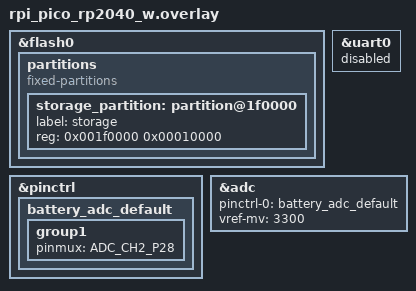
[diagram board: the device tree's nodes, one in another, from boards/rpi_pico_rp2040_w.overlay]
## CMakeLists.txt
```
cmake_minimum_required(VERSION 3.20.0)
find_package(Zephyr REQUIRED HINTS $ENV{ZEPHYR_BASE})
project(ham_lab_powermeter)
target_sources(app PRIVATE src/main.c src/curves/curves_core.c src/curves/curves_store.c src/network/network.c src/network/tcp_console.c src/network/ntp_clock.c)
```

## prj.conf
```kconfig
CONFIG_GPIO=y
CONFIG_NETWORKING=y
CONFIG_NET_IPV4=y
CONFIG_NET_DHCPV4=y
CONFIG_NET_TCP=y
CONFIG_NET_SOCKETS=y
CONFIG_WIFI=y
CONFIG_NET_MGMT=y
CONFIG_NET_MGMT_EVENT=y
CONFIG_NET_SHELL=y
CONFIG_SHELL=y
CONFIG_SHELL_BACKEND_SERIAL=y
CONFIG_SHELL_BACKEND_TELNET=n
CONFIG_SHELL_BACKEND_DUMMY=y
CONFIG_SHELL_BACKEND_DUMMY_BUF_SIZE=8192
CONFIG_MAIN_STACK_SIZE=4096
CONFIG_SYSTEM_WORKQUEUE_STACK_SIZE=2048
CONFIG_HEAP_MEM_POOL_SIZE=8192
CONFIG_LOG=y
CONFIG_PICOLIBC_IO_FLOAT=y
CONFIG_UDC_DRIVER_LOG_LEVEL_OFF=y
CONFIG_SHELL_STACK_SIZE=5200
CONFIG_NET_TX_STACK_SIZE=2048
CONFIG_NET_RX_STACK_SIZE=2048
CONFIG_NET_PKT_RX_COUNT=16
CONFIG_NET_PKT_TX_COUNT=32
CONFIG_NET_BUF_RX_COUNT=32
CONFIG_NET_BUF_TX_COUNT=64
CONFIG_NET_MAX_CONTEXTS=16
CONFIG_NET_MAX_CONN=16
CONFIG_WIFI_USAGE_MODE_STA_AP=y
CONFIG_NET_L2_WIFI_MGMT=y
CONFIG_NET_L2_WIFI_SHELL=y
CONFIG_NET_CONNECTION_MANAGER=y
CONFIG_NET_MGMT_EVENT_STACK_SIZE=1536
CONFIG_NET_MGMT_EVENT_QUEUE_TIMEOUT=5000
CONFIG_NET_MGMT_EVENT_QUEUE_SIZE=16
CONFIG_WIFI_CREDENTIALS=y
CONFIG_WIFI_CREDENTIALS_BACKEND_SETTINGS=y
CONFIG_SETTINGS=y
CONFIG_FLASH=y
CONFIG_FLASH_MAP=y
CONFIG_NVS=y
CONFIG_SETTINGS_NVS=y
CONFIG_USBD_CDC_ACM_BUF_POOL=y
CONFIG_USBD_CDC_ACM_BUF_POOL_SIZE=4096

# RP2040 bring-up: timer-based RNG for Zephyr networking (not cryptographic).
CONFIG_TEST_RANDOM_GENERATOR=y
CONFIG_TIMER_RANDOM_GENERATOR=y

# UTC measurement timestamps from NTP over WLAN.
CONFIG_NET_UDP=y
CONFIG_DNS_RESOLVER=y
CONFIG_NET_DHCPV4_OPTION_DNS_ADDRESS=y
CONFIG_SNTP=y

CONFIG_ADC=y

# AP test: native DHCP server, two clients; mode remains RAM-only.
CONFIG_NET_DHCPV4_SERVER=y
CONFIG_NET_DHCPV4_SERVER_ADDR_COUNT=2
CONFIG_NET_MGMT_EVENT_INFO=y
```

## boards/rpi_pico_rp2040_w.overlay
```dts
#include <zephyr/dt-bindings/pinctrl/rpi-pico-rp2040-pinctrl.h>
/* Powermeter GPIO pins are configured directly by the application. */

/* Pico W: reserve final 64 KiB of 2 MiB flash for Settings/NVS. */
&flash0 {
    partitions {
        compatible = "fixed-partitions";
        #address-cells = <1>;
        #size-cells = <1>;

        storage_partition: partition@1f0000 {
            label = "storage";
            reg = <0x001f0000 0x00010000>;
        };
    };
};

/* GP0/GP1 belong to software I2C; console is USB CDC ACM. */
&uart0 { status = "disabled"; };

&pinctrl {
    battery_adc_default: battery_adc_default {
        group1 { pinmux = <ADC_CH2_P28>; };
    };
};
&adc {
    status = "okay";
    pinctrl-0 = <&battery_adc_default>;
    pinctrl-names = "default";
    vref-mv = <3300>;
};
```

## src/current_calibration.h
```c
#ifndef CURRENT_CALIBRATION_H
#define CURRENT_CALIBRATION_H
#include <math.h>
#include <stdbool.h>
#include <stddef.h>
#include "curves/curves_store.h"
/* Paired A0 master / A2 measurements, 2026-10-06, 7.1 MHz.
 * A0 watts are the reference, not ICOM percentage or former scope curve.
 * 1 percent excluded: A0 below calibrated floor. 90/100 percent pooled:
 * indistinguishable A2 voltage within sample scatter. Endpoint guards cover
 * only observed endpoint sample voltages, with constant endpoint watts.
 * Resistive 50 ohms ONLY. No extrapolation outside measured voltage bounds. */
#define CURRENT_CALIBRATION_HZ 7100000U
#define CURRENT_MIN_W (hamlab_curve(CURVE_CURRENT)->points[0].w)
#define CURRENT_MAX_W (current_max_w())
#define CURRENT_PLATEAU_V (current_plateau_v())
static const __attribute__((unused)) struct {double v,w;} current_curve[]={
    {0.019687500000,1.494300000000},
    {0.019713566667,1.494300000000},
    {0.039494800000,2.104700000000},
    {0.056960933333,2.586900000000},
    {0.086549466667,3.726366666667},
    {0.243015633333,10.410466666667},
    {0.281750000000,12.822733333333},
    {0.321697900000,16.678633333333},
    {0.385187500000,25.142500000000},
    {0.436041666667,35.765400000000},
    {0.479604166667,47.222500000000},
    {0.502822933333,55.466933333333},
    {0.525354166667,65.059266666667},
    {0.543625000000,74.074366666667},
    {0.558520816667,83.346166666667},
    {0.560062500000,83.346166666667},
};
static inline double current_max_w(void){const struct curve_data *c=hamlab_curve(CURVE_CURRENT);return c->points[c->count-1].w;}
static inline double current_plateau_v(void){
    const struct curve_data *c=hamlab_curve(CURVE_CURRENT);size_t i=c->count-1;
    while(i>0&&c->points[i-1].w==c->points[c->count-1].w)i--;
    return c->points[i].v;
}
static inline bool current_power(double v,double *w){
    return curves_interpolate(hamlab_curve(CURVE_CURRENT),v,w);
}
#endif
```

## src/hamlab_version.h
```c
#ifndef HAMLAB_VERSION_H_
#define HAMLAB_VERSION_H_

#define HAMLAB_VERSION "0.1.49"

#endif
```

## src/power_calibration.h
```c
#ifndef POWER_CALIBRATION_H
#define POWER_CALIBRATION_H
#include <stdbool.h>
#include <stddef.h>
#include <math.h>
#include "curves/curves_store.h"
/* ADC-side voltages, divider included. Scope sine Vpp^2/(8*50).
 * Provisional, ONLY measured at 7031670 Hz. No extrapolation or zero anchor. */
static const __attribute__((unused)) struct { double v, w; } forward_curve[] = {
    {0.0556641,1.2544},
    {0.0860469,1.6384},
    {0.1380937,2.2500},
    {0.1790000,2.7556},
    {0.2404375,4.0000},
    {0.5645938,10.7584},
    {0.6690312,13.2496},
    {0.7982813,17.3056},
    {1.0539375,26.0100},
    {1.3049375,37.2100},
    {1.5681875,49.0000},
    {1.7332500,57.7600},
    {1.8861250,67.2400},
    {2.0262500,75.6900},
    {2.1535000,84.6400},
    {2.2778750,92.1600},
};
static inline bool forward_power(double v, double *w) {
    return curves_interpolate(hamlab_curve(CURVE_FORWARD),v,w);
}
/* Reversed coupler, 50-ohm reference, averaged/pooled repetitions.
 * Runtime selection is RAM-only. No automatic RF frequency detection. */
static unsigned int reverse_calibration_hz=7100000;
struct reverse_cal_point { double v,w; };
static const __attribute__((unused)) struct reverse_cal_point reverse_curve_7100000[]={
    {0.0530182333,1.3456000000},
    {0.0829349000,1.7424000000},
    {0.1362760333,2.4336000000},
    {0.2390937333,3.9469333333},
    {0.5619895667,11.6512000000},
    {0.6655833333,14.5418666667},
    {0.7942083667,18.4330666667},
    {1.0455833333,29.5233333333},
    {1.2900625000,39.6900000000},
    {1.5458750000,53.7800000000},
    {1.7054166667,61.8866666667},
    {1.8639166667,72.8200000000},
    {1.9976250000,82.8100000000},
    {2.0872083333,88.9900000000},
};
static const __attribute__((unused)) struct reverse_cal_point reverse_curve_50100000[]={
    {0.0249869667,1.1096000000},
    {0.0444479333,1.3768000000},
    {0.0852552000,1.9790666667},
    {0.1664192667,3.1450666667},
    {0.4418229333,9.2426666667},
    {0.5395625000,11.9258666667},
    {0.6560625000,15.4736000000},
    {0.9020000000,25.6733333333},
    {1.1729375000,38.4400000000},
    {1.4391458333,52.8066666667},
    {1.5773958333,62.4100000000},
    {1.6880000000,68.8966666667},
    {1.6989166667,70.0100000000},
    {1.7051250000,70.5600000000},
};
static inline enum curve_id reverse_id(void){return reverse_calibration_hz==50100000?CURVE_REVERSE_50:CURVE_REVERSE_7;}
static inline double reverse_min_v(void){return hamlab_curve(reverse_id())->points[0].v;}
static inline double reverse_min_w(void){return hamlab_curve(reverse_id())->points[0].w;}
static inline double reverse_max_w(void){const struct curve_data *c=hamlab_curve(reverse_id());return c->points[c->count-1].w;}
static inline bool swr_calibration_compatible(void){return reverse_calibration_hz==7100000;}
static inline bool reverse_power(double v,double *w){return curves_interpolate(hamlab_curve(reverse_id()),v,w);}
static inline bool calibrated_swr(double pf,double pr,double *swr){
    if(!isfinite(pf)||!isfinite(pr)||pf<=0||pr<0||pr>=pf)return false;
    double rho=sqrt(pr/pf);*swr=(1+rho)/(1-rho);return isfinite(*swr);
}
#endif
```
